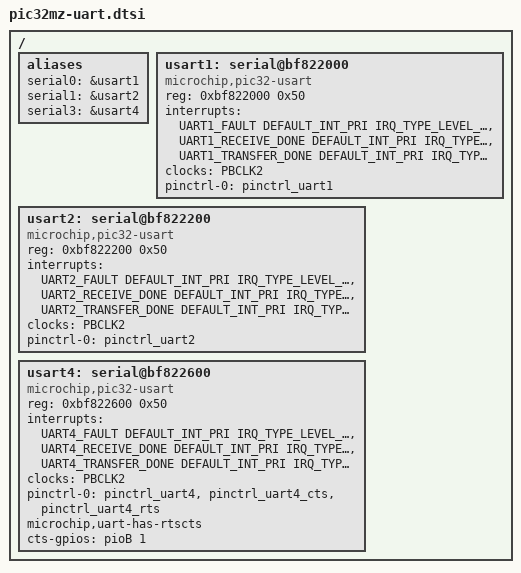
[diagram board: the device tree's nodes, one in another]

/ {
	aliases {
		serial0 = &usart1;
		serial1 = &usart2;
		serial3 = &usart4;
	};

	usart1: serial@bf822000 {
		compatible = "microchip,pic32-usart";
		reg = <0xbf822000 0x50>;
		interrupts = <UART1_FAULT DEFAULT_INT_PRI IRQ_TYPE_LEVEL_HIGH>,
			     <UART1_RECEIVE_DONE DEFAULT_INT_PRI IRQ_TYPE_LEVEL_HIGH>,
			     <UART1_TRANSFER_DONE DEFAULT_INT_PRI IRQ_TYPE_LEVEL_HIGH>;
		clocks = <&PBCLK2>;
		pinctrl-names = "default";
		pinctrl-0 = <
			&pinctrl_uart1>;
	};

	usart2: serial@bf822200 {
		compatible = "microchip,pic32-usart";
		reg = <0xbf822200 0x50>;
		interrupts = <UART2_FAULT DEFAULT_INT_PRI IRQ_TYPE_LEVEL_HIGH>,
			     <UART2_RECEIVE_DONE DEFAULT_INT_PRI IRQ_TYPE_LEVEL_HIGH>,
			     <UART2_TRANSFER_DONE DEFAULT_INT_PRI IRQ_TYPE_LEVEL_HIGH>;
		clocks = <&PBCLK2>;
		pinctrl-names = "default";
		pinctrl-0 = <
			&pinctrl_uart2>;
	};

	usart4: serial@bf822600 {
		compatible = "microchip,pic32-usart";
		reg = <0xbf822600 0x50>;
		interrupts = <UART4_FAULT DEFAULT_INT_PRI IRQ_TYPE_LEVEL_HIGH>,
			     <UART4_RECEIVE_DONE DEFAULT_INT_PRI IRQ_TYPE_LEVEL_HIGH>,
			     <UART4_TRANSFER_DONE DEFAULT_INT_PRI IRQ_TYPE_LEVEL_HIGH>;
		clocks = <&PBCLK2>;
		pinctrl-names = "default";
		pinctrl-0 = <
			&pinctrl_uart4
			&pinctrl_uart4_cts
			&pinctrl_uart4_rts>;
		microchip,uart-has-rtscts;
		cts-gpios = <&pioB 1 0>;
		/*rts-gpios = <&pioD 10 0>;*/
	};
};
